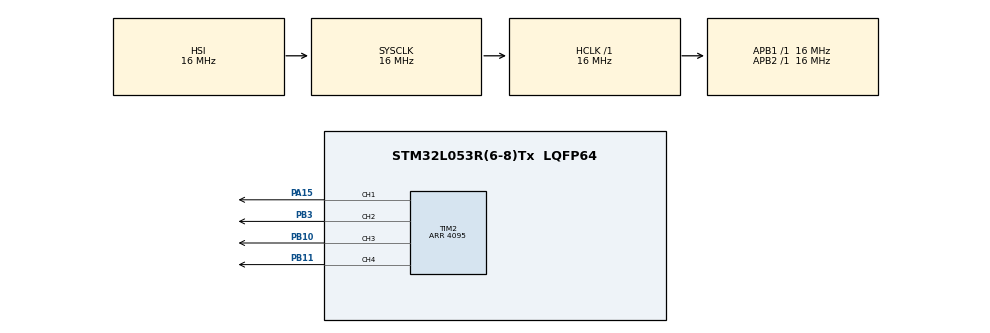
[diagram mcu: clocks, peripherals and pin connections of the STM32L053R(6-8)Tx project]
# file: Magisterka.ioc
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Mcu.Family=STM32L0
Mcu.Name=STM32L053R(6-8)Tx
Mcu.Package=LQFP64
PA15.Signal=S_TIM2_CH1
PB10.Signal=S_TIM2_CH3
PB11.Signal=S_TIM2_CH4
PB3.Signal=S_TIM2_CH2
ProjectManager.HeapSize=0x200
ProjectManager.StackSize=0x400
ProjectManager.TargetToolchain=SW4STM32
RCC.AHBFreq_Value=16000000
RCC.APB1Freq_Value=16000000
RCC.APB1TimFreq_Value=16000000
RCC.APB2Freq_Value=16000000
RCC.APB2TimFreq_Value=16000000
RCC.HCLKFreq_Value=16000000
RCC.HSE_VALUE=8000000
RCC.HSI16_VALUE=16000000
RCC.HSI48_VALUE=48000000
RCC.HSI_VALUE=16000000
RCC.LSE_VALUE=32768
RCC.MSI_VALUE=2097000
RCC.SYSCLKFreq_VALUE=16000000
RCC.SYSCLKSource=RCC_SYSCLKSOURCE_HSI
RCC.VCOOutputFreq_Value=48000000
SH.S_TIM2_CH1.0=TIM2_CH1,PWM Generation1 CH1
SH.S_TIM2_CH2.0=TIM2_CH2,PWM Generation2 CH2
SH.S_TIM2_CH3.0=TIM2_CH3,PWM Generation3 CH3
SH.S_TIM2_CH4.0=TIM2_CH4,PWM Generation4 CH4
TIM2.Channel-PWM\ Generation2\ CH2=TIM_CHANNEL_2
TIM2.Channel-PWM\ Generation3\ CH3=TIM_CHANNEL_3
TIM2.Channel-PWM\ Generation4\ CH4=TIM_CHANNEL_4
TIM2.Period=4095
TIM2.Pulse-PWM\ Generation1\ CH1=50
TIM2.Pulse-PWM\ Generation2\ CH2=60
TIM2.Pulse-PWM\ Generation3\ CH3=70
TIM2.Pulse-PWM\ Generation4\ CH4=80
VP_TIM2_VS_ClockSourceINT.Mode=Internal
board=Magisterka

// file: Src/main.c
/**
  ******************************************************************************
  * File Name          : main.c
  * Description        : Main program body
  ******************************************************************************
  *
  * COPYRIGHT(c) 2018 STMicroelectronics
  *
  * Redistribution and use in source and binary forms, with or without modification,
  * are permitted provided that the following conditions are met:
  *   1. Redistributions of source code must retain the above copyright notice,
  *      this list of conditions and the following disclaimer.
  *   2. Redistributions in binary form must reproduce the above copyright notice,
  *      this list of conditions and the following disclaimer in the documentation
  *      and/or other materials provided with the distribution.
  *   3. Neither the name of STMicroelectronics nor the names of its contributors
  *      may be used to endorse or promote products derived from this software
  *      without specific prior written permission.
  *
  * THIS SOFTWARE IS PROVIDED BY THE COPYRIGHT HOLDERS AND CONTRIBUTORS "AS IS"
  * AND ANY EXPRESS OR IMPLIED WARRANTIES, INCLUDING, BUT NOT LIMITED TO, THE
  * IMPLIED WARRANTIES OF MERCHANTABILITY AND FITNESS FOR A PARTICULAR PURPOSE ARE
  * DISCLAIMED. IN NO EVENT SHALL THE COPYRIGHT HOLDER OR CONTRIBUTORS BE LIABLE
  * FOR ANY DIRECT, INDIRECT, INCIDENTAL, SPECIAL, EXEMPLARY, OR CONSEQUENTIAL
  * DAMAGES (INCLUDING, BUT NOT LIMITED TO, PROCUREMENT OF SUBSTITUTE GOODS OR
  * SERVICES; LOSS OF USE, DATA, OR PROFITS; OR BUSINESS INTERRUPTION) HOWEVER
  * CAUSED AND ON ANY THEORY OF LIABILITY, WHETHER IN CONTRACT, STRICT LIABILITY,
  * OR TORT (INCLUDING NEGLIGENCE OR OTHERWISE) ARISING IN ANY WAY OUT OF THE USE
  * OF THIS SOFTWARE, EVEN IF ADVISED OF THE POSSIBILITY OF SUCH DAMAGE.
  *
  ******************************************************************************
  */
#include "main.h"
#include "stm32l0xx_hal.h"

/* USER CODE BEGIN Includes */
#include "comm.h"
#include "adc.h"
#include "gpio.h"
/* USER CODE END Includes */

TIM_HandleTypeDef htim2;

/* USER CODE BEGIN PV */
/* Private variables ---------------------------------------------------------*/

/* USER CODE END PV */

void SystemClock_Config(void);
void Error_Handler(void);
static void MX_GPIO_Init(void);
static void MX_TIM2_Init(void);
void HAL_TIM_MspPostInit(TIM_HandleTypeDef *htim);

/* USER CODE BEGIN PFP */
/* Private function prototypes -----------------------------------------------*/

/* USER CODE END PFP */

int main(void)
{

  /* MCU Configuration----------------------------------------------------------*/

  /* Reset of all peripherals, Initializes the Flash interface and the Systick. */
  HAL_Init();

  /* Configure the system clock */
  SystemClock_Config();

  /* Initialize all configured peripherals */
  MX_GPIO_Init();
  MX_TIM2_Init();

  /* USER CODE BEGIN 2 */
  initializeADCPins();
  initializeADC();
  initializePWM();
  disableHalfTransferIT();
  initializeReceive();
  initializeDigitalPins();
  initializeUART();
  initializeDMA();
  /* USER CODE END 2 */

  /* Infinite loop */
  while (1)
  {

  /* USER CODE BEGIN 3 */
	 //GetMeasures();
	 //setAllPWM(halves);
	  //writeDigital(0x3F);
	 //readDigital();
	 HAL_Delay(100);
  }
  /* USER CODE END 3 */

}

/** System Clock Configuration
*/
void SystemClock_Config(void)
{

  RCC_OscInitTypeDef RCC_OscInitStruct;
  RCC_ClkInitTypeDef RCC_ClkInitStruct;

    /**Configure the main internal regulator output voltage
    */
  __HAL_PWR_VOLTAGESCALING_CONFIG(PWR_REGULATOR_VOLTAGE_SCALE1);

    /**Initializes the CPU, AHB and APB busses clocks
    */
  RCC_OscInitStruct.OscillatorType = RCC_OSCILLATORTYPE_HSI;
  RCC_OscInitStruct.HSIState = RCC_HSI_ON;
  RCC_OscInitStruct.HSICalibrationValue = 16;
  RCC_OscInitStruct.PLL.PLLState = RCC_PLL_NONE;
  if (HAL_RCC_OscConfig(&RCC_OscInitStruct) != HAL_OK)
  {
    Error_Handler();
  }

    /**Initializes the CPU, AHB and APB busses clocks
    */
  RCC_ClkInitStruct.ClockType = RCC_CLOCKTYPE_HCLK|RCC_CLOCKTYPE_SYSCLK
                              |RCC_CLOCKTYPE_PCLK1|RCC_CLOCKTYPE_PCLK2;
  RCC_ClkInitStruct.SYSCLKSource = RCC_SYSCLKSOURCE_HSI;
  RCC_ClkInitStruct.AHBCLKDivider = RCC_SYSCLK_DIV1;
  RCC_ClkInitStruct.APB1CLKDivider = RCC_HCLK_DIV1;
  RCC_ClkInitStruct.APB2CLKDivider = RCC_HCLK_DIV1;

  if (HAL_RCC_ClockConfig(&RCC_ClkInitStruct, FLASH_LATENCY_0) != HAL_OK)
  {
    Error_Handler();
  }

    /**Configure the Systick interrupt time
    */
  HAL_SYSTICK_Config(HAL_RCC_GetHCLKFreq()/1000);

    /**Configure the Systick
    */
  HAL_SYSTICK_CLKSourceConfig(SYSTICK_CLKSOURCE_HCLK);

  /* SysTick_IRQn interrupt configuration */
  HAL_NVIC_SetPriority(SysTick_IRQn, 0, 0);
}

/* TIM2 init function */
static void MX_TIM2_Init(void)
{

  TIM_ClockConfigTypeDef sClockSourceConfig;
  TIM_MasterConfigTypeDef sMasterConfig;
  TIM_OC_InitTypeDef sConfigOC;

  htim2.Instance = TIM2;
  htim2.Init.Prescaler = 0;
  htim2.Init.CounterMode = TIM_COUNTERMODE_UP;
  htim2.Init.Period = 4095;
  htim2.Init.ClockDivision = TIM_CLOCKDIVISION_DIV1;
  if (HAL_TIM_Base_Init(&htim2) != HAL_OK)
  {
    Error_Handler();
  }

  sClockSourceConfig.ClockSource = TIM_CLOCKSOURCE_INTERNAL;
  if (HAL_TIM_ConfigClockSource(&htim2, &sClockSourceConfig) != HAL_OK)
  {
    Error_Handler();
  }

  if (HAL_TIM_PWM_Init(&htim2) != HAL_OK)
  {
    Error_Handler();
  }

  sMasterConfig.MasterOutputTrigger = TIM_TRGO_RESET;
  sMasterConfig.MasterSlaveMode = TIM_MASTERSLAVEMODE_DISABLE;
  if (HAL_TIMEx_MasterConfigSynchronization(&htim2, &sMasterConfig) != HAL_OK)
  {
    Error_Handler();
  }

  sConfigOC.OCMode = TIM_OCMODE_PWM1;
  sConfigOC.Pulse = 50;
  sConfigOC.OCPolarity = TIM_OCPOLARITY_HIGH;
  sConfigOC.OCFastMode = TIM_OCFAST_DISABLE;
  if (HAL_TIM_PWM_ConfigChannel(&htim2, &sConfigOC, TIM_CHANNEL_1) != HAL_OK)
  {
    Error_Handler();
  }

  sConfigOC.Pulse = 60;
  if (HAL_TIM_PWM_ConfigChannel(&htim2, &sConfigOC, TIM_CHANNEL_2) != HAL_OK)
  {
    Error_Handler();
  }

  sConfigOC.Pulse = 70;
  if (HAL_TIM_PWM_ConfigChannel(&htim2, &sConfigOC, TIM_CHANNEL_3) != HAL_OK)
  {
    Error_Handler();
  }

  sConfigOC.Pulse = 80;
  if (HAL_TIM_PWM_ConfigChannel(&htim2, &sConfigOC, TIM_CHANNEL_4) != HAL_OK)
  {
    Error_Handler();
  }

  HAL_TIM_MspPostInit(&htim2);

}

/** Pinout Configuration
*/
static void MX_GPIO_Init(void)
{

  /* GPIO Ports Clock Enable */
  __HAL_RCC_GPIOB_CLK_ENABLE();
  __HAL_RCC_GPIOA_CLK_ENABLE();

}

void Error_Handler(void)
{
  while(1)
  {
  }
}

/************************ (C) COPYRIGHT STMicroelectronics *****END OF FILE****/
